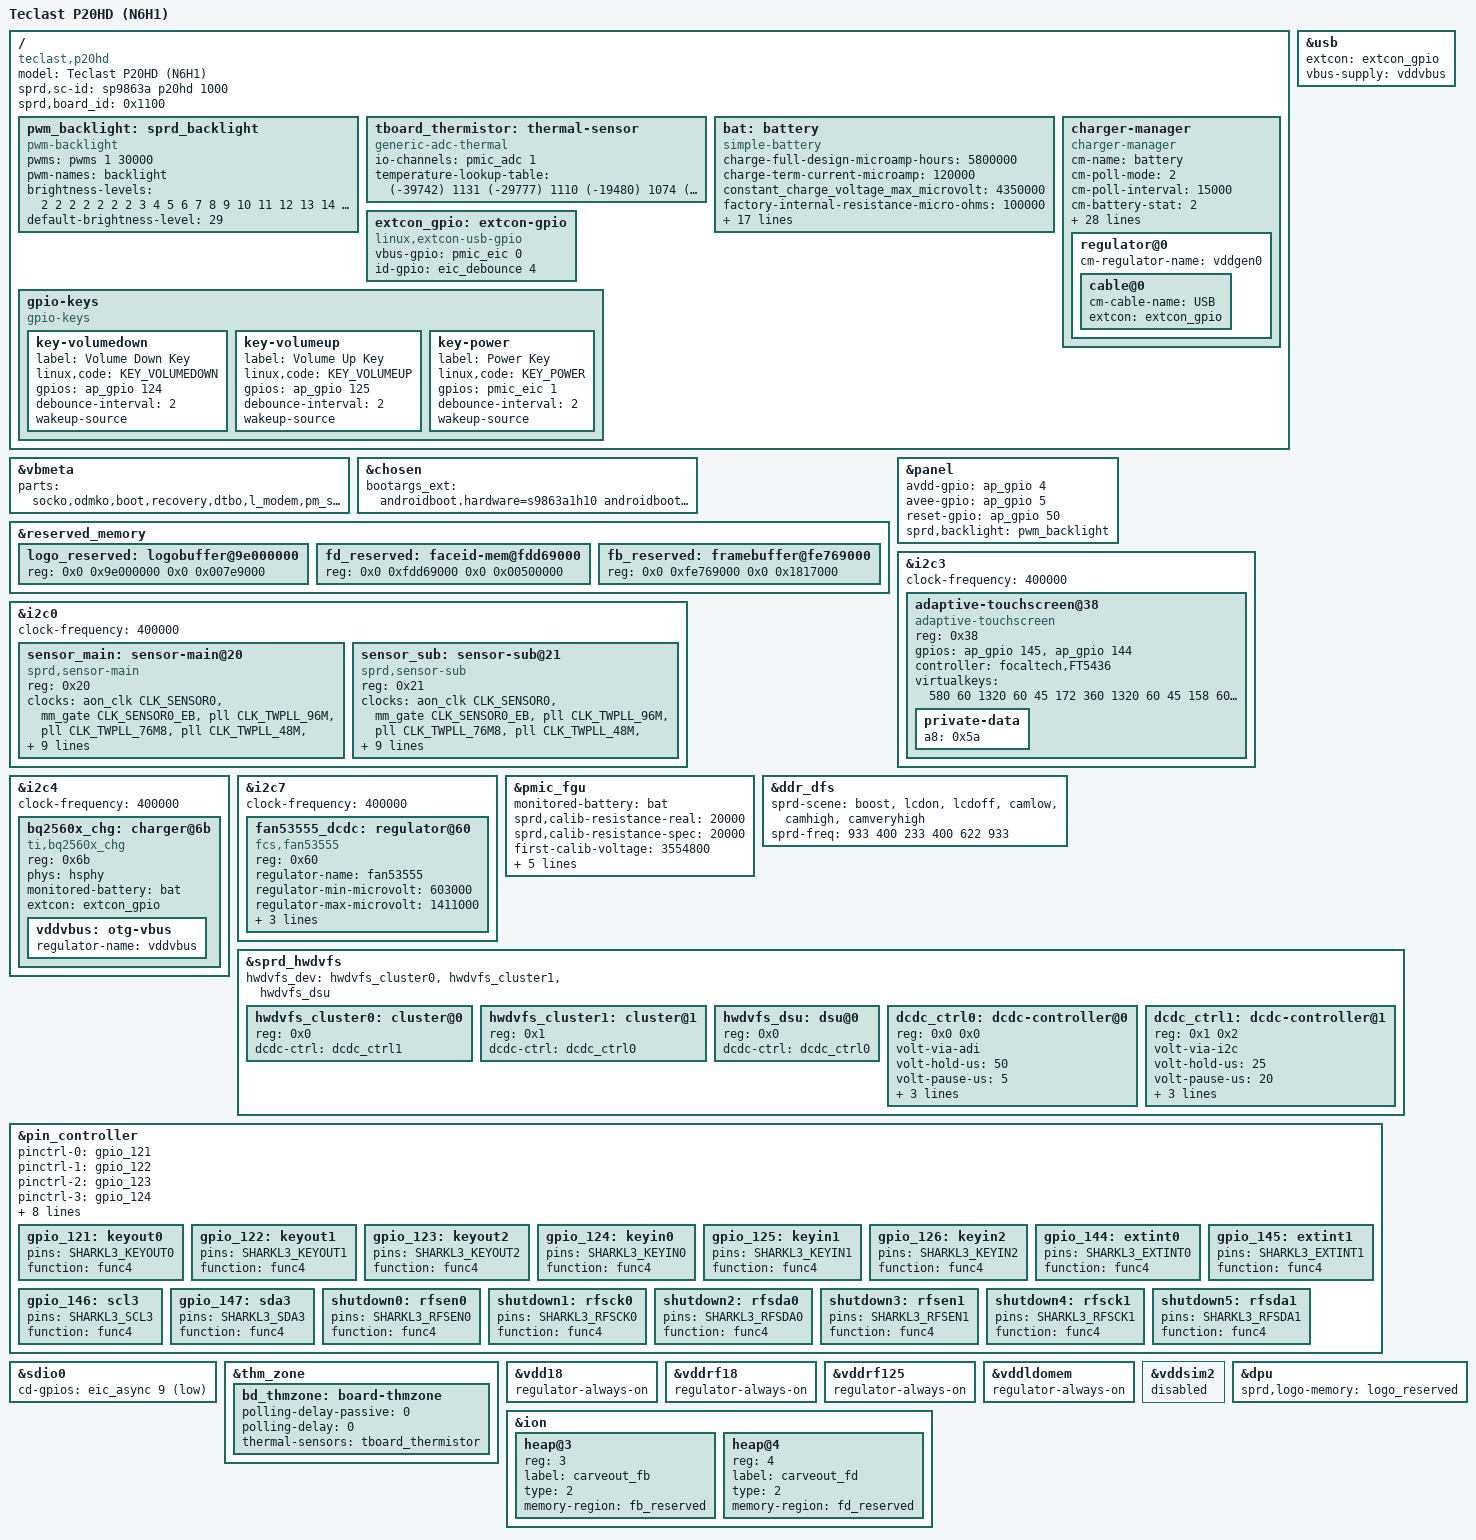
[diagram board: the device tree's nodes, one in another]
// SPDX-License-Identifier: GPL-2.0-only
/*
 * Teclast P20HD (N6H1) Device Tree Overlay
 *
 * SoC: Unisoc SC9863A (Sharkl3)
 * Display: ILI9881C 720x1280 MIPI DSI
 * Touch: FocalTech FT5436 @ I2C3:0x38
 * Charger: TI BQ2560x @ I2C4:0x6b
 * Battery: 5800mAh
 *
 * Based on sp9863a-1h10-overlay.dts
 */

/dts-v1/;
/plugin/;

#include <dt-bindings/input/input.h>
#include <dt-bindings/gpio/gpio.h>
#include <dt-bindings/clock/sprd,sc9863a-clk.h>
#include "lcd/lcd_ili9881c_truly_mipi_hd.dtsi"
#include "lcd/lcd_dummy_mipi.dtsi"

/ {
	model = "Teclast P20HD (N6H1)";
	compatible = "teclast,p20hd", "sprd,sp9863a-1h10", "sprd,sc9863a";
	sprd,sc-id = "sp9863a p20hd 1000";
	sprd,board_id = <0x1100>;

	fragment {
		target-path = "/";
		__overlay__ {
			pwm_backlight: sprd_backlight {
				compatible = "pwm-backlight";
				pwms = <&pwms 1 30000>;
				pwm-names = "backlight";
				brightness-levels = <
								  2   2   2   2
					  2   2   2   3   4   5   6   7   8   9
					 10  11  12  13  14  15  16  17  18  19
					 20  21  22  23  24  25  26  27  28  29
					 30  31  32  33  34  35  36  37  38  39
					 40  41  42  43  44  45  46  47  48  49
					 50  51  52  53  54  55  56  57  58  59
					 60  61  62  63  64  65  66  67  68  69
					 70  71  72  73  74  75  76  77  78  79
					 80  81  82  83  84  85  86  87  88  89
					 90  91  92  93  94  95  96  97  98  99
					100 101 102 103 104 105 106 107 108 109
					110 111 112 113 114 115 116 117 118 119
					120 121 122 123 124 125 126 127 128 129
					130 131 132 133 134 135 136 137 138 139
					140 141 142 143 144 145 146 147 148 149
					150 151 152 153 154 155 156 157 158 159
					160 161 162 163 164 165 166 167 168 169
					170 171 172 173 174 175 176 177 178 179
					180 181 182 183 184 185 186 187 188 189
					190 191 192 193 194 195 196 197 198 199
					200 201 202 203 204 205 206 207 208 209
					210 211 212 213 214 215 216 217 218 219
					220 221 222 223 224 225 226 227 228 229
					230 231 232 233 234 235 236 237 238 239
					240 241 242 243 244 245 246 247 248 249
					250 251
				>;
				default-brightness-level = <29>;
			};

			tboard_thermistor: thermal-sensor {
				compatible = "generic-adc-thermal";
				#thermal-sensor-cells = <0>;
				io-channels = <&pmic_adc 1>;
				io-channel-names = "sensor-channel";
				temperature-lookup-table = <	(-39742) 1131
								(-29777) 1110
								(-19480) 1074
								(-4679) 983
								10110 838
								24805 654
								44922 413
								54903 316
								64895 238
								74884 178
								84883 133
								94883 100
								104880 75
								114889 57
								124872 43 >;
			};

			/* Teclast P20HD Battery: 5800mAh */
			bat: battery {
				compatible = "simple-battery";
				charge-full-design-microamp-hours = <5800000>;
				charge-term-current-microamp = <120000>;
				constant_charge_voltage_max_microvolt = <4350000>;
				factory-internal-resistance-micro-ohms = <100000>;
				voltage-min-design-microvolt = <3450000>;
				ocv-capacity-celsius = <20>;
				ocv-capacity-table-0 = <4310000 100>, <4249000 95>, <4189000 90>,
							<4133000 85>, <4081000 80>, <4034000 75>,
							<3991000 70>, <3953000 65>, <3910000 60>,
							<3866000 55>, <3836000 50>, <3813000 45>,
							<3795000 40>, <3782000 35>, <3774000 30>,
							<3765000 25>, <3750000 20>, <3726000 15>,
							<3687000 10>, <3658000 5>, <3500000 0>;
				capacity-temp-table = <25 100>, <10 97>, <(-10) 60>;
				resistance-temp-table = <20 100>, <10 243>, <(-10) 468>;
				charge-sdp-current-microamp = <1700000 1850000>;
				charge-dcp-current-microamp = <1700000 1850000>;
				charge-cdp-current-microamp = <1700000 1850000>;
				charge-unknown-current-microamp = <1700000 1850000>;
			};

			charger-manager {
				status = "okay";
				compatible = "charger-manager";
				cm-name = "battery";
				cm-poll-mode = <2>;
				cm-poll-interval = <15000>;
				cm-battery-stat = <2>;

				cm-fullbatt-vchkdrop-ms = <30000>;
				cm-fullbatt-vchkdrop-volt = <60000>;
				cm-fullbatt-voltage = <4310000>;
				cm-fullbatt-current = <250000>;
				cm-fullbatt-capacity = <100>;

				cm-num-chargers = <1>;
				cm-chargers = "bq2560x_charger";
				cm-fuel-gauge = "sc27xx-fgu";

				/* in deci centigrade */
				cm-battery-cold = <200>;
				cm-battery-cold-in-minus;
				cm-battery-hot = <800>;
				cm-battery-temp-diff = <100>;

				/* Allow charging for 6hr */
				cm-charging-max = <21600000>;
				/* recovery charging after stop charging 45min */
				cm-discharging-max = <2700000>;

				/* the interval to feed charger watchdog */
				cm-wdt-interval = <60>;

				/* drop voltage in microVolts to allow shutdown */
				cm-shutdown-voltage = <3100000>;

				/* when 99% of the time is exceeded, it will be forced to 100% */
				cm-tickle-time-out = <500>;

				/* how much time to allow capacity change */
				cm-one-cap-time = <30>;

				/* when the safe charging voltage is exceeded, stop charging */
				cm-charge-voltage-max = <6500000>;
				/* drop voltage in microVolts to restart charging */
				cm-charge-voltage-drop = <700000>;

				cm-jeita-temp-table = <1000 1050 1500000 4350000>,
					<1150 1200 1850000 4350000>,
					<1480 1430 1850000 4350000>,
					<1580 1530 1500000 4350000>;

				monitored-battery = <&bat>;

				cm-cap-remap-table = <1 2 3>, <2 3 2>, <98 99 2>, <99 100 3>;

				regulator@0 {
					cm-regulator-name = "vddgen0";
					cable@0 {
						cm-cable-name = "USB";
						extcon = <&extcon_gpio>;
					};
				};
			};

			extcon_gpio: extcon-gpio {
				compatible = "linux,extcon-usb-gpio";
				vbus-gpio = <&pmic_eic 0 0>;
				id-gpio = <&eic_debounce 4 0>;
			};

			gpio-keys {
				compatible = "gpio-keys";

				key-volumedown {
					label = "Volume Down Key";
					linux,code = <KEY_VOLUMEDOWN>;
					gpios = <&ap_gpio 124 GPIO_ACTIVE_HIGH>;
					debounce-interval = <2>;
					wakeup-source;
				};

				key-volumeup {
					label = "Volume Up Key";
					linux,code = <KEY_VOLUMEUP>;
					gpios = <&ap_gpio 125 GPIO_ACTIVE_HIGH>;
					debounce-interval = <2>;
					wakeup-source;
				};

				key-power {
					label = "Power Key";
					linux,code = <KEY_POWER>;
					gpios = <&pmic_eic 1 GPIO_ACTIVE_HIGH>;
					debounce-interval = <2>;
					wakeup-source;
				};
			};
		};
	};
};

&vbmeta {
	parts = "socko,odmko,boot,recovery,dtbo,l_modem,pm_sys,l_ldsp,l_gdsp";
};

&chosen {
	bootargs_ext = "androidboot.hardware=s9863a1h10 androidboot.dtbo_idx=0";
};

&reserved_memory {
	logo_reserved: logobuffer@9e000000 {
		reg = <0x0 0x9e000000 0x0 0x007e9000>;
	};

	fd_reserved: faceid-mem@fdd69000 {
		reg = <0x0 0xfdd69000 0x0 0x00500000>;
	};

	fb_reserved: framebuffer@fe769000 {
		reg = <0x0 0xfe769000 0x0 0x1817000>;
	};
};

&usb {
	extcon = <&extcon_gpio>;
	vbus-supply = <&vddvbus>;
};

&panel {
	avdd-gpio = <&ap_gpio 4 GPIO_ACTIVE_HIGH>;
	avee-gpio = <&ap_gpio 5 GPIO_ACTIVE_HIGH>;
	reset-gpio = <&ap_gpio 50 GPIO_ACTIVE_HIGH>;
	sprd,backlight = <&pwm_backlight>;
};

/* Camera sensors - P20HD has dual cameras */
&i2c0 {
	status = "okay";
	clock-frequency = <400000>;

	sensor_main: sensor-main@20 {
		compatible = "sprd,sensor-main";
		reg = <0x20>;
		clock-names = "clk_src", "sensor_eb",
			"clk_96m", "clk_76m8",
			"clk_48m", "clk_26m";
		clocks = <&aon_clk CLK_SENSOR0>, <&mm_gate CLK_SENSOR0_EB>,
			<&pll CLK_TWPLL_96M>, <&pll CLK_TWPLL_76M8>,
			<&pll CLK_TWPLL_48M>, <&ext_26m>;
		vddio-supply = <&vddcamio>;
		vddcama-supply = <&vddcama>;
		vddcamd-supply = <&vddcamd>;
		vddcammot-supply = <&vddcammot>;
		sprd,phyid = <1>;
		csi = <&csi0>;
		reset-gpios = <&ap_gpio 44 0>;
		power-down-gpios = <&ap_gpio 46 0>;
	};

	sensor_sub: sensor-sub@21 {
		compatible = "sprd,sensor-sub";
		reg = <0x21>;
		clock-names = "clk_src", "sensor_eb",
			"clk_96m", "clk_76m8",
			"clk_48m", "clk_26m";
		clocks = <&aon_clk CLK_SENSOR0>, <&mm_gate CLK_SENSOR0_EB>,
			<&pll CLK_TWPLL_96M>, <&pll CLK_TWPLL_76M8>,
			<&pll CLK_TWPLL_48M>, <&ext_26m>;
		vddio-supply = <&vddcamio>;
		vddcama-supply = <&vddcama>;
		vddcamd-supply = <&vddcamd>;
		vddcammot-supply = <&vddcammot>;
		sprd,phyid = <3>;
		csi = <&csi1>;
		reset-gpios = <&ap_gpio 44 0>;
		power-down-gpios = <&ap_gpio 40 0>;
	};
};

/* Touch controller: FocalTech FT5436 */
&i2c3 {
	status = "okay";
	clock-frequency = <400000>;

	adaptive-touchscreen@38 {
		compatible = "adaptive-touchscreen";
		reg = <0x38>;
		gpios = <&ap_gpio 145 GPIO_ACTIVE_HIGH
			&ap_gpio 144 GPIO_ACTIVE_HIGH>;
		controller = "focaltech,FT5436";
		/* Virtual keys: back, home, menu */
		virtualkeys = <580 60 1320 60 45
			172 360 1320 60 45
			158 600 1320 60 45>;
		private-data {
			a8 = /bits/ 8 <0x5a>;
		};
	};
};

/* Charger: TI BQ2560x */
&i2c4 {
	status = "okay";
	clock-frequency = <400000>;

	bq2560x_chg: charger@6b {
		compatible = "ti,bq2560x_chg";
		reg = <0x6b>;
		phys = <&hsphy>;
		monitored-battery = <&bat>;
		extcon = <&extcon_gpio>;

		vddvbus: otg-vbus {
			regulator-name = "vddvbus";
		};
	};
};

/* DCDC regulator */
&i2c7 {
	status = "okay";
	clock-frequency = <400000>;

	fan53555_dcdc: regulator@60 {
		compatible = "fcs,fan53555";
		reg = <0x60>;
		regulator-name = "fan53555";
		regulator-min-microvolt = <603000>;
		regulator-max-microvolt = <1411000>;
		regulator-ramp-delay = <64000>;
		regulator-always-on;
		fcs,suspend-voltage-selector = <1>;
	};
};

&pmic_fgu {
	monitored-battery = <&bat>;
	sprd,calib-resistance-real = <20000>;
	sprd,calib-resistance-spec = <20000>;
	first-calib-voltage = <3554800>;
	first-calib-capacity = <50>;
	fgu-capacity-track;
	fullbatt-track-end-vol = <4295>;
	fullbatt-track-end-cur = <130>;
	phys = <&hsphy>;
};

&ddr_dfs {
	sprd-scene = "boost", "lcdon", "lcdoff", "camlow",
			"camhigh", "camveryhigh";
	sprd-freq = <933 400 233 400 622 933>;
};

&sprd_hwdvfs {
	hwdvfs_dev = <&hwdvfs_cluster0>,
		<&hwdvfs_cluster1>,
		<&hwdvfs_dsu>;

	hwdvfs_cluster0: cluster@0 {
		reg = <0x0>;
		dcdc-ctrl = <&dcdc_ctrl1>;
	};

	hwdvfs_cluster1: cluster@1 {
		reg = <0x1>;
		dcdc-ctrl = <&dcdc_ctrl0>;
	};

	hwdvfs_dsu: dsu@0 {
		reg = <0x0>;
		dcdc-ctrl = <&dcdc_ctrl0>;
	};

	dcdc_ctrl0: dcdc-controller@0 {
		reg = <0x0 0x0>;
		volt-via-adi;
		volt-hold-us = <50>;
		volt-pause-us = <5>;
		volt-timeout-us = <800>;
		volt-stable-us = <5>;
		volt-max-step-microvolt = <25000>;
	};

	dcdc_ctrl1: dcdc-controller@1 {
		reg = <0x1 0x2>;
		volt-via-i2c;
		volt-hold-us = <25>;
		volt-pause-us = <20>;
		volt-timeout-us = <800>;
		volt-stable-us = <25>;
		volt-max-step-microvolt = <1200004>;
	};
};

&pin_controller {
	pinctrl-names =
	/* keyout0 ~ keyout2 */
	"gpio_121", "gpio_122", "gpio_123",
	/* keyin0 ~ keyin2 */
	"gpio_124", "gpio_125", "gpio_126",
	/* extint0, extint1, scl3, sda3 */
	"gpio_144", "gpio_145", "gpio_146", "gpio_147",
	"shutdown";
	pinctrl-0 = <&gpio_121>;
	pinctrl-1 = <&gpio_122>;
	pinctrl-2 = <&gpio_123>;
	pinctrl-3 = <&gpio_124>;
	pinctrl-4 = <&gpio_125>;
	pinctrl-5 = <&gpio_126>;
	pinctrl-6 = <&gpio_144>;
	pinctrl-7 = <&gpio_145>;
	pinctrl-8 = <&gpio_146>;
	pinctrl-9 = <&gpio_147>;
	pinctrl-10 = <&shutdown0
			&shutdown1
			&shutdown2
			&shutdown3
			&shutdown4
			&shutdown5>;

	gpio_121: keyout0 {
		pins = "SHARKL3_KEYOUT0";
		function = "func4";
	};

	gpio_122: keyout1 {
		pins = "SHARKL3_KEYOUT1";
		function = "func4";
	};

	gpio_123: keyout2 {
		pins = "SHARKL3_KEYOUT2";
		function = "func4";
	};

	gpio_124: keyin0 {
		pins = "SHARKL3_KEYIN0";
		function = "func4";
	};

	gpio_125: keyin1 {
		pins = "SHARKL3_KEYIN1";
		function = "func4";
	};

	gpio_126: keyin2 {
		pins = "SHARKL3_KEYIN2";
		function = "func4";
	};

	gpio_144: extint0 {
		pins = "SHARKL3_EXTINT0";
		function = "func4";
	};

	gpio_145: extint1 {
		pins = "SHARKL3_EXTINT1";
		function = "func4";
	};

	gpio_146: scl3 {
		pins = "SHARKL3_SCL3";
		function = "func4";
	};

	gpio_147: sda3 {
		pins = "SHARKL3_SDA3";
		function = "func4";
	};

	shutdown0: rfsen0 {
		pins = "SHARKL3_RFSEN0";
		function = "func4";
	};

	shutdown1: rfsck0 {
		pins = "SHARKL3_RFSCK0";
		function = "func4";
	};

	shutdown2: rfsda0 {
		pins = "SHARKL3_RFSDA0";
		function = "func4";
	};

	shutdown3: rfsen1 {
		pins = "SHARKL3_RFSEN1";
		function = "func4";
	};

	shutdown4: rfsck1 {
		pins = "SHARKL3_RFSCK1";
		function = "func4";
	};

	shutdown5: rfsda1 {
		pins = "SHARKL3_RFSDA1";
		function = "func4";
	};
};

&sdio0 {
	cd-gpios = <&eic_async 9 1>;
};

&thm_zone {
	bd_thmzone: board-thmzone {
		polling-delay-passive = <0>;
		polling-delay = <0>;
		thermal-sensors = <&tboard_thermistor>;
	};
};

&vdd18 {
	regulator-always-on;
};

&vddrf18 {
	regulator-always-on;
};

&vddrf125 {
	regulator-always-on;
};

&vddldomem {
	regulator-always-on;
};

&vddsim2 {
	status = "disabled";
};

&ion {
	heap@3 {
		reg = <3>;
		label = "carveout_fb";
		type = <2>;
		memory-region = <&fb_reserved>;
	};
	heap@4 {
		reg = <4>;
		label = "carveout_fd";
		type = <2>;
		memory-region = <&fd_reserved>;
	};
};

&dpu {
	sprd,logo-memory = <&logo_reserved>;
};
